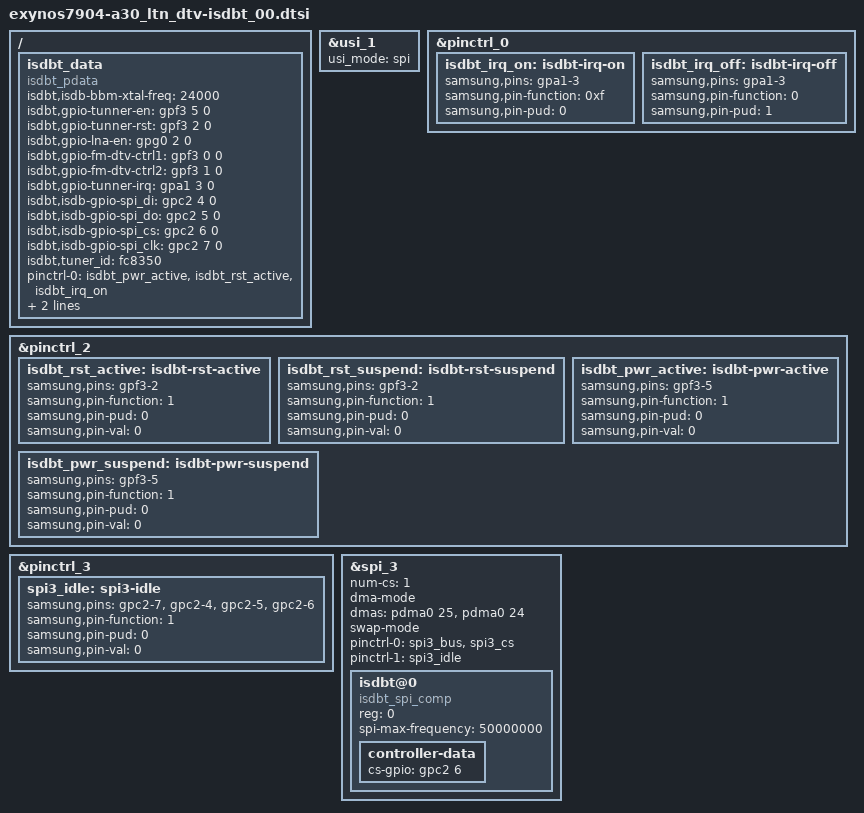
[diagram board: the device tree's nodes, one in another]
 /* Copyright (c) 2012-2014, The Linux Foundation. All rights reserved.
 *
 * This program is free software; you can redistribute it and/or modify
 * it under the terms of the GNU General Public License version 2 and
 * only version 2 as published by the Free Software Foundation.
 *
 * This program is distributed in the hope that it will be useful,
 * but WITHOUT ANY WARRANTY; without even the implied warranty of
 * MERCHANTABILITY or FITNESS FOR A PARTICULAR PURPOSE.  See the
 * GNU General Public License for more details.
 */

&usi_1 {
	usi_mode = "spi";
	status = "okay";
};
 
&pinctrl_0 {
	isdbt_irq_on: isdbt-irq-on {
		samsung,pins = "gpa1-3";
		samsung,pin-function = <0xf>;
		samsung,pin-pud = <0>;	/* PULL NONE */
	};
	isdbt_irq_off: isdbt-irq-off {
		samsung,pins = "gpa1-3";
		samsung,pin-function = <0>; /* INPUT */
		samsung,pin-pud = <1>;	/* PULL DOWN */
	};
		
};
 
&pinctrl_2{
	isdbt_rst_active: isdbt-rst-active {
		samsung,pins = "gpf3-2";
		samsung,pin-function = <1>;
		samsung,pin-pud = <0>;
		samsung,pin-val = <0>;
	};
	isdbt_rst_suspend: isdbt-rst-suspend {
		samsung,pins = "gpf3-2";
		samsung,pin-function = <1>;
		samsung,pin-pud = <0>;
		samsung,pin-val = <0>;
	};
	
	isdbt_pwr_active: isdbt-pwr-active {
		samsung,pins = "gpf3-5";
		samsung,pin-function = <1>;
		samsung,pin-pud = <0>;
		samsung,pin-val = <0>;
	};
	isdbt_pwr_suspend: isdbt-pwr-suspend {
		samsung,pins = "gpf3-5";
		samsung,pin-function = <1>;
		samsung,pin-pud = <0>;
		samsung,pin-val = <0>;
	};
}; 
 
&pinctrl_3 {
	spi3_idle: spi3-idle {
		samsung,pins = "gpc2-7", "gpc2-4", "gpc2-5", "gpc2-6";
		samsung,pin-function = <1>;
		samsung,pin-pud = <0>;
		samsung,pin-val = <0>;
	};	
};

&spi_3 {
	num-cs = <1>;
	status = "ok";

	dma-mode;
	dmas = <&pdma0 25
		&pdma0 24>;

	swap-mode;
	/*spi-clkoff-time = <100>;*/

	pinctrl-names = "default","idle";
	pinctrl-0 = <&spi3_bus &spi3_cs>;
	pinctrl-1 = <&spi3_idle>;

	isdbt@0 {
		compatible = "isdbt_spi_comp";
		reg = <0>;
		spi-max-frequency = <50000000>;
		controller-data {
		cs-gpio = <&gpc2 6 0>;
		/*samsung,spi-feedback-delay = <3>;*/
		};
	};
};
	
/ {	
	fragment@isdbt_data {
		target-path = "/";
		__overlay__ {	
			isdbt_data {
				compatible = "isdbt_pdata";

				isdbt,isdb-bbm-xtal-freq = <24000>;
				isdbt,gpio-tunner-en = <&gpf3 5 0>;
				isdbt,gpio-tunner-rst = <&gpf3 2 0>;
				isdbt,gpio-lna-en = <&gpg0 2 0>;
				isdbt,gpio-fm-dtv-ctrl1 = <&gpf3 0 0>;
				isdbt,gpio-fm-dtv-ctrl2 = <&gpf3 1 0>;
				isdbt,gpio-tunner-irq = <&gpa1 3 0>;
		

				isdbt,isdb-gpio-spi_di = <&gpc2 4 0>;
				isdbt,isdb-gpio-spi_do = <&gpc2 5 0>;
				isdbt,isdb-gpio-spi_cs = <&gpc2 6 0>;
				isdbt,isdb-gpio-spi_clk = <&gpc2 7 0>;

				isdbt,tuner_id = "fc8350";

				pinctrl-names = "isdbt_gpio_active", "isdbt_gpio_suspend";
				pinctrl-0 = <&isdbt_pwr_active &isdbt_rst_active &isdbt_irq_on>;
				pinctrl-1 = <&isdbt_pwr_suspend &isdbt_rst_suspend &isdbt_irq_off>;
			};
		};
	};
};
